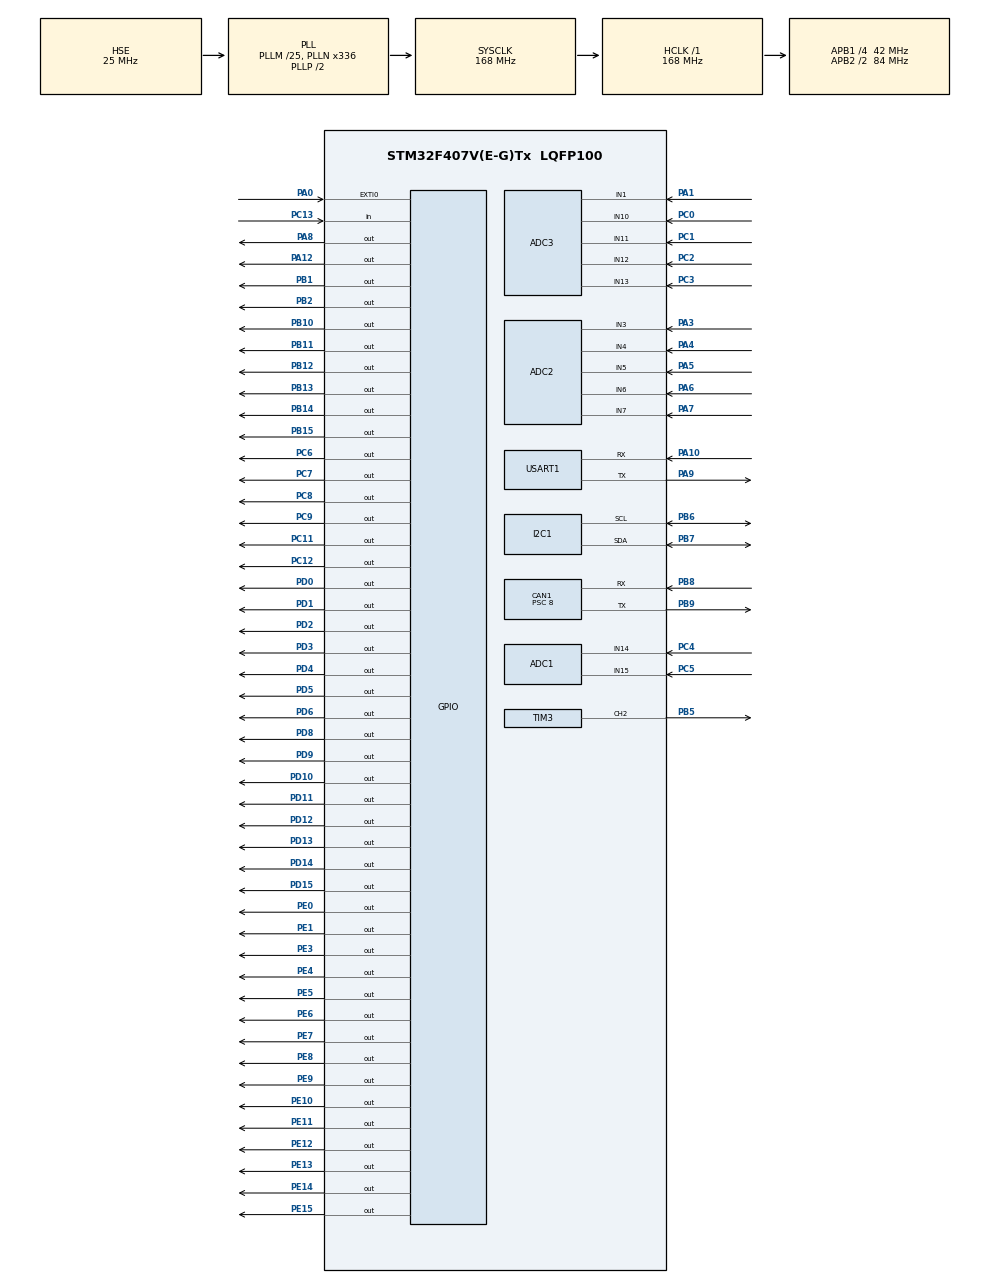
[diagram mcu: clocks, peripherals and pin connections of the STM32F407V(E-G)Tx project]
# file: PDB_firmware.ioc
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ADC1.Channel-0\#ChannelRegularConversion=ADC_CHANNEL_14
ADC1.Channel-1\#ChannelRegularConversion=ADC_CHANNEL_15
ADC1.ClockPrescaler=ADC_CLOCK_SYNC_PCLK_DIV4
ADC1.ContinuousConvMode=ENABLE
ADC1.DMAContinuousRequests=ENABLE
ADC1.NbrOfConversion=2
ADC1.NbrOfConversionFlag=1
ADC1.Rank-0\#ChannelRegularConversion=1
ADC1.Rank-1\#ChannelRegularConversion=2
ADC1.SamplingTime-0\#ChannelRegularConversion=ADC_SAMPLETIME_3CYCLES
ADC1.SamplingTime-1\#ChannelRegularConversion=ADC_SAMPLETIME_3CYCLES
ADC1.master=1
ADC2.Channel-0\#ChannelRegularConversion=ADC_CHANNEL_3
ADC2.Channel-1\#ChannelRegularConversion=ADC_CHANNEL_4
ADC2.Channel-2\#ChannelRegularConversion=ADC_CHANNEL_5
ADC2.Channel-3\#ChannelRegularConversion=ADC_CHANNEL_6
ADC2.Channel-4\#ChannelRegularConversion=ADC_CHANNEL_7
ADC2.ClockPrescaler=ADC_CLOCK_SYNC_PCLK_DIV4
ADC2.ContinuousConvMode=ENABLE
ADC2.DMAContinuousRequests=ENABLE
ADC2.NbrOfConversion=5
ADC2.NbrOfConversionFlag=1
ADC2.Rank-0\#ChannelRegularConversion=1
ADC2.Rank-1\#ChannelRegularConversion=2
ADC2.Rank-2\#ChannelRegularConversion=3
ADC2.Rank-3\#ChannelRegularConversion=4
ADC2.Rank-4\#ChannelRegularConversion=5
ADC2.SamplingTime-0\#ChannelRegularConversion=ADC_SAMPLETIME_3CYCLES
ADC2.SamplingTime-1\#ChannelRegularConversion=ADC_SAMPLETIME_3CYCLES
ADC2.SamplingTime-2\#ChannelRegularConversion=ADC_SAMPLETIME_3CYCLES
ADC2.SamplingTime-3\#ChannelRegularConversion=ADC_SAMPLETIME_3CYCLES
ADC2.SamplingTime-4\#ChannelRegularConversion=ADC_SAMPLETIME_3CYCLES
ADC3.Channel-0\#ChannelRegularConversion=ADC_CHANNEL_10
ADC3.Channel-1\#ChannelRegularConversion=ADC_CHANNEL_11
ADC3.Channel-2\#ChannelRegularConversion=ADC_CHANNEL_12
ADC3.Channel-3\#ChannelRegularConversion=ADC_CHANNEL_13
ADC3.Channel-4\#ChannelRegularConversion=ADC_CHANNEL_1
ADC3.ClockPrescaler=ADC_CLOCK_SYNC_PCLK_DIV4
ADC3.DMAContinuousRequests=ENABLE
ADC3.NbrOfConversion=5
ADC3.NbrOfConversionFlag=1
ADC3.Rank-0\#ChannelRegularConversion=1
ADC3.Rank-1\#ChannelRegularConversion=2
ADC3.Rank-2\#ChannelRegularConversion=3
ADC3.Rank-3\#ChannelRegularConversion=4
ADC3.Rank-4\#ChannelRegularConversion=5
ADC3.SamplingTime-0\#ChannelRegularConversion=ADC_SAMPLETIME_3CYCLES
ADC3.SamplingTime-1\#ChannelRegularConversion=ADC_SAMPLETIME_3CYCLES
ADC3.SamplingTime-2\#ChannelRegularConversion=ADC_SAMPLETIME_3CYCLES
ADC3.SamplingTime-3\#ChannelRegularConversion=ADC_SAMPLETIME_3CYCLES
ADC3.SamplingTime-4\#ChannelRegularConversion=ADC_SAMPLETIME_3CYCLES
CAN1.BS1=CAN_BS1_14TQ
CAN1.BS2=CAN_BS2_6TQ
CAN1.CalculateBaudRate=250000
CAN1.CalculateTimeBit=4000
CAN1.CalculateTimeQuantum=190.47619047619048
CAN1.Prescaler=8
Dma.ADC1.0.Direction=DMA_PERIPH_TO_MEMORY
Dma.ADC1.0.FIFOMode=DMA_FIFOMODE_DISABLE
Dma.ADC1.0.Instance=DMA2_Stream0
Dma.ADC1.0.MemDataAlignment=DMA_MDATAALIGN_HALFWORD
Dma.ADC1.0.MemInc=DMA_MINC_ENABLE
Dma.ADC1.0.Mode=DMA_NORMAL
Dma.ADC1.0.PeriphDataAlignment=DMA_PDATAALIGN_HALFWORD
Dma.ADC1.0.PeriphInc=DMA_PINC_DISABLE
Dma.ADC1.0.Priority=DMA_PRIORITY_LOW
Dma.ADC2.1.Direction=DMA_PERIPH_TO_MEMORY
Dma.ADC2.1.FIFOMode=DMA_FIFOMODE_DISABLE
Dma.ADC2.1.Instance=DMA2_Stream2
Dma.ADC2.1.MemDataAlignment=DMA_MDATAALIGN_HALFWORD
Dma.ADC2.1.MemInc=DMA_MINC_ENABLE
Dma.ADC2.1.Mode=DMA_NORMAL
Dma.ADC2.1.PeriphDataAlignment=DMA_PDATAALIGN_HALFWORD
Dma.ADC2.1.PeriphInc=DMA_PINC_DISABLE
Dma.ADC2.1.Priority=DMA_PRIORITY_VERY_HIGH
Dma.ADC3.2.Direction=DMA_PERIPH_TO_MEMORY
Dma.ADC3.2.FIFOMode=DMA_FIFOMODE_DISABLE
Dma.ADC3.2.Instance=DMA2_Stream1
Dma.ADC3.2.MemDataAlignment=DMA_MDATAALIGN_HALFWORD
Dma.ADC3.2.MemInc=DMA_MINC_ENABLE
Dma.ADC3.2.Mode=DMA_NORMAL
Dma.ADC3.2.PeriphDataAlignment=DMA_PDATAALIGN_HALFWORD
Dma.ADC3.2.PeriphInc=DMA_PINC_DISABLE
Dma.ADC3.2.Priority=DMA_PRIORITY_LOW
Dma.Request0=ADC1
Dma.Request1=ADC2
Dma.Request2=ADC3
FREERTOS.CountingSemaphores01=OLEDoccupiedSem,32,Dynamic,NULL
FREERTOS.Events01=MonitorAnalyzeEvent,Dynamic,NULL;CanReceiveEvent,Dynamic,NULL
FREERTOS.INCLUDE_xEventGroupSetBitFromISR=1
FREERTOS.Queues01=AVDataQueue,32,uint8_t,0,Dynamic,NULL,NULL;AVErrorQueue,16,uint16_t,0,Dynamic,NULL,NULL;CanReceiveQueue,16,uint8_t,0,Dynamic,NULL,NULL;OLEDtoCANerrorSend,8,uint16_t,0,Dynamic,NULL,NULL
FREERTOS.Tasks01=CanErrorSendTas,48,128,Start_CAN_Error_Send_Task,Default,NULL,Dynamic,NULL,NULL;BATdetectTask,8,128,Start_BAT_Detect_Task,Default,NULL,Dynamic,NULL,NULL;OLEDmonitorTask,40,128,Start_OLED_Monitor_Task,Default,NULL,Dynamic,NULL,NULL;CanDataSendTask,48,128,Start_CAN_Data_Send_Task,Default,NULL,Dynamic,NULL,NULL;CANreceiveTask,48,128,Start_CAN_Receive_Task,Default,NULL,Dynamic,NULL,NULL;HSDctrlTask,48,128,Start_HSD_Ctrl_Task,Default,NULL,Dynamic,NULL,NULL;DRSctrlTask,8,128,Start_DRS_Ctrl_Task,Default,NULL,Dynamic,NULL,NULL;WakeupTask,8,128,Start_Wakeup_Task,Default,NULL,Dynamic,NULL,NULL;StandbyTask,55,128,Start_Standby_Task,Default,NULL,Dynamic,NULL,NULL;HSD1diagnosTask,8,128,Start_HSD1_Diagnose_Task,Default,NULL,Dynamic,NULL,NULL;HSD2diagnosTask,8,128,Start_HSD2_Diagnose_Task,Default,NULL,Dynamic,NULL,NULL;CPUTask,8,256,Start_CPU_Task,Default,NULL,Dynamic,NULL,NULL
I2C1.I2C_Mode=I2C_Fast
Mcu.Family=STM32F4
Mcu.Name=STM32F407V(E-G)Tx
Mcu.Package=LQFP100
NVIC.CAN1_RX0_IRQn=true\:5\:0\:true\:false\:true\:true\:true\:true\:true
NVIC.DMA2_Stream0_IRQn=true\:5\:0\:false\:false\:true\:true\:false\:true\:true
NVIC.DMA2_Stream1_IRQn=true\:5\:0\:false\:false\:true\:true\:false\:true\:true
NVIC.DMA2_Stream2_IRQn=true\:5\:0\:false\:false\:true\:true\:false\:true\:true
NVIC.EXTI0_IRQn=true\:5\:0\:false\:false\:true\:true\:true\:true\:true
NVIC.PriorityGroup=NVIC_PRIORITYGROUP_4
NVIC.TIM6_DAC_IRQn=true\:5\:0\:true\:false\:true\:true\:true\:true\:true
NVIC.TIM8_TRG_COM_TIM14_IRQn=true\:15\:0\:false\:false\:true\:false\:false\:true\:true
NVIC.TimeBase=TIM8_TRG_COM_TIM14_IRQn
NVIC.TimeBaseIP=TIM14
PA0-WKUP.GPIO_ModeDefaultEXTI=GPIO_MODE_IT_FALLING
PA0-WKUP.Signal=GPXTI0
PA1.Signal=ADCx_IN1
PA10.Mode=Asynchronous
PA10.Signal=USART1_RX
PA12.Signal=GPIO_Output
PA13.Mode=Serial_Wire
PA13.Signal=SYS_JTMS-SWDIO
PA14.Mode=Serial_Wire
PA14.Signal=SYS_JTCK-SWCLK
PA3.Signal=ADCx_IN3
PA4.Signal=ADCx_IN4
PA5.Signal=ADCx_IN5
PA6.Signal=ADCx_IN6
PA7.Signal=ADCx_IN7
PA8.Signal=GPIO_Output
PA9.Mode=Asynchronous
PA9.Signal=USART1_TX
PB1.Signal=GPIO_Output
PB10.Signal=GPIO_Output
PB11.Signal=GPIO_Output
PB12.Signal=GPIO_Output
PB13.Signal=GPIO_Output
PB14.Signal=GPIO_Output
PB15.Signal=GPIO_Output
PB2.Signal=GPIO_Output
PB5.GPIO_Speed=GPIO_SPEED_FREQ_HIGH
PB5.Signal=S_TIM3_CH2
PB6.GPIO_Pu=GPIO_PULLUP
PB6.Mode=I2C
PB6.Signal=I2C1_SCL
PB7.GPIO_Pu=GPIO_PULLUP
PB7.Mode=I2C
PB7.Signal=I2C1_SDA
PB8.GPIO_PuPd=GPIO_PULLUP
PB8.Mode=CAN_Activate
PB8.Signal=CAN1_RX
PB9.GPIO_PuPd=GPIO_PULLUP
PB9.Mode=CAN_Activate
PB9.Signal=CAN1_TX
PC0.Signal=ADCx_IN10
PC1.Signal=ADCx_IN11
PC11.Signal=GPIO_Output
PC12.Signal=GPIO_Output
PC13-ANTI_TAMP.Signal=GPIO_Input
PC2.Signal=ADCx_IN12
PC3.Signal=ADCx_IN13
PC4.Signal=ADCx_IN14
PC5.Signal=ADCx_IN15
PC6.Signal=GPIO_Output
PC7.Signal=GPIO_Output
PC8.Signal=GPIO_Output
PC9.Signal=GPIO_Output
PD0.Signal=GPIO_Output
PD1.Signal=GPIO_Output
PD10.Signal=GPIO_Output
PD11.Signal=GPIO_Output
PD12.Signal=GPIO_Output
PD13.Signal=GPIO_Output
PD14.Signal=GPIO_Output
PD15.Signal=GPIO_Output
PD2.Signal=GPIO_Output
PD3.Signal=GPIO_Output
PD4.Signal=GPIO_Output
PD5.Signal=GPIO_Output
PD6.Signal=GPIO_Output
PD8.Signal=GPIO_Output
PD9.Signal=GPIO_Output
PE0.Signal=GPIO_Output
PE1.Signal=GPIO_Output
PE10.Signal=GPIO_Output
PE11.Signal=GPIO_Output
PE12.Signal=GPIO_Output
PE13.Signal=GPIO_Output
PE14.Signal=GPIO_Output
PE15.Signal=GPIO_Output
PE3.Signal=GPIO_Output
PE4.Signal=GPIO_Output
PE5.Signal=GPIO_Output
PE6.Signal=GPIO_Output
PE7.Signal=GPIO_Output
PE8.Signal=GPIO_Output
PE9.Signal=GPIO_Output
PH0-OSC_IN.Mode=HSE-External-Oscillator
PH0-OSC_IN.Signal=RCC_OSC_IN
PH1-OSC_OUT.Mode=HSE-External-Oscillator
PH1-OSC_OUT.Signal=RCC_OSC_OUT
ProjectManager.HeapSize=0x200
ProjectManager.StackSize=0x400
ProjectManager.TargetToolchain=MDK-ARM V5.32
RCC.48MHZClocksFreq_Value=84000000
RCC.AHBFreq_Value=168000000
RCC.APB1CLKDivider=RCC_HCLK_DIV4
RCC.APB1Freq_Value=42000000
RCC.APB1TimFreq_Value=84000000
RCC.APB2CLKDivider=RCC_HCLK_DIV2
RCC.APB2Freq_Value=84000000
RCC.APB2TimFreq_Value=168000000
RCC.CortexFreq_Value=168000000
RCC.HCLKFreq_Value=168000000
RCC.HSE_VALUE=25000000
RCC.HSI_VALUE=16000000
RCC.LSE_VALUE=32768
RCC.PLLM=25
RCC.PLLN=336
RCC.PLLSourceVirtual=RCC_PLLSOURCE_HSE
RCC.SYSCLKFreq_VALUE=168000000
RCC.SYSCLKSource=RCC_SYSCLKSOURCE_PLLCLK
RCC.VCOOutputFreq_Value=336000000
SH.ADCx_IN1.0=ADC3_IN1,IN1
SH.ADCx_IN10.0=ADC3_IN10,IN10
SH.ADCx_IN11.0=ADC3_IN11,IN11
SH.ADCx_IN12.0=ADC3_IN12,IN12
SH.ADCx_IN13.0=ADC3_IN13,IN13
SH.ADCx_IN14.0=ADC1_IN14,IN14
SH.ADCx_IN15.0=ADC1_IN15,IN15
SH.ADCx_IN3.0=ADC2_IN3,IN3
SH.ADCx_IN4.0=ADC2_IN4,IN4
SH.ADCx_IN5.0=ADC2_IN5,IN5
SH.ADCx_IN6.0=ADC2_IN6,IN6
SH.ADCx_IN7.0=ADC2_IN7,IN7
SH.S_TIM3_CH2.0=TIM3_CH2,PWM Generation2 CH2
TIM3.Channel-PWM\ Generation2\ CH2=TIM_CHANNEL_2
TIM3.Period=99
TIM3.Prescaler=1679
TIM4.Period=999
TIM4.Prescaler=1679
TIM6.Period=209
TIM6.Prescaler=19
USART1.VirtualMode=VM_ASYNC
VP_FREERTOS_VS_CMSIS_V2.Mode=CMSIS_V2
VP_SYS_VS_tim14.Mode=TIM14
VP_TIM3_VS_ClockSourceINT.Mode=Internal
VP_TIM4_VS_ClockSourceINT.Mode=Internal
VP_TIM6_VS_ClockSourceINT.Mode=Enable_Timer
board=custom

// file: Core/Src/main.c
/* USER CODE BEGIN Header */
/**
  ******************************************************************************
  * @file           : main.c
  * @brief          : Main program body
  ******************************************************************************
  * @attention
  *
  * Copyright (c) 2024 STMicroelectronics.
  * All rights reserved.
  *
  * This software is licensed under terms that can be found in the LICENSE file
  * in the root directory of this software component.
  * If no LICENSE file comes with this software, it is provided AS-IS.
  *
  ******************************************************************************
  */
/* USER CODE END Header */
#include "main.h"
#include "cmsis_os.h"
#include "adc.h"
#include "can.h"
#include "dma.h"
#include "i2c.h"
#include "tim.h"
#include "usart.h"
#include "gpio.h"

/* USER CODE BEGIN Includes */
//bsp
#include "hsd_drive.h"
#include "mycan.h"
#include "oled.h"
#include "oledfont.h"
#include "myusart.h"
#include "voltage_monitor.h"
//app
#include "can_app.h"
#include "oled_app.h"
/* USER CODE END Includes */

void SystemClock_Config(void);
void MX_FREERTOS_Init(void);

/* USER CODE BEGIN 0 */
//分析32位bit数呈现为二进制时1的个数
int count_one_bits(unsigned int value)
{
  int count = 0;
  while (value)
  {
    value &= (value - 1);//
    count++;
  }
  return count;
}

/* USER CODE END 0 */

int main(void)
{

  /* MCU Configuration--------------------------------------------------------*/

  /* Reset of all peripherals, Initializes the Flash interface and the Systick. */
  HAL_Init();

  /* Configure the system clock */
  SystemClock_Config();

  /* Initialize all configured peripherals */
  MX_GPIO_Init();
  MX_DMA_Init();
  MX_ADC1_Init();
  MX_ADC2_Init();
  MX_ADC3_Init();
  MX_CAN1_Init();
  MX_USART1_UART_Init();
  MX_I2C1_Init();
  MX_TIM3_Init();
  MX_TIM6_Init();
  MX_TIM4_Init();

  /* Init scheduler */
  osKernelInitialize();

  /* Call init function for freertos objects (in freertos.c) */
  MX_FREERTOS_Init();

  /* Start scheduler */
  osKernelStart();

  /* We should never get here as control is now taken by the scheduler */
  /* Infinite loop */
  while (1)
  {

  }
}

void SystemClock_Config(void)
{
  RCC_OscInitTypeDef RCC_OscInitStruct = {0};
  RCC_ClkInitTypeDef RCC_ClkInitStruct = {0};

  /** Configure the main internal regulator output voltage
  */
  __HAL_RCC_PWR_CLK_ENABLE();
  __HAL_PWR_VOLTAGESCALING_CONFIG(PWR_REGULATOR_VOLTAGE_SCALE1);

  /** Initializes the RCC Oscillators according to the specified parameters
  * in the RCC_OscInitTypeDef structure.
  */
  RCC_OscInitStruct.OscillatorType = RCC_OSCILLATORTYPE_HSE;
  RCC_OscInitStruct.HSEState = RCC_HSE_ON;
  RCC_OscInitStruct.PLL.PLLState = RCC_PLL_ON;
  RCC_OscInitStruct.PLL.PLLSource = RCC_PLLSOURCE_HSE;
  RCC_OscInitStruct.PLL.PLLM = 25;
  RCC_OscInitStruct.PLL.PLLN = 336;
  RCC_OscInitStruct.PLL.PLLP = RCC_PLLP_DIV2;
  RCC_OscInitStruct.PLL.PLLQ = 4;
  if (HAL_RCC_OscConfig(&RCC_OscInitStruct) != HAL_OK)
  {
    Error_Handler();
  }

  /** Initializes the CPU, AHB and APB buses clocks
  */
  RCC_ClkInitStruct.ClockType = RCC_CLOCKTYPE_HCLK|RCC_CLOCKTYPE_SYSCLK
                              |RCC_CLOCKTYPE_PCLK1|RCC_CLOCKTYPE_PCLK2;
  RCC_ClkInitStruct.SYSCLKSource = RCC_SYSCLKSOURCE_PLLCLK;
  RCC_ClkInitStruct.AHBCLKDivider = RCC_SYSCLK_DIV1;
  RCC_ClkInitStruct.APB1CLKDivider = RCC_HCLK_DIV4;
  RCC_ClkInitStruct.APB2CLKDivider = RCC_HCLK_DIV2;

  if (HAL_RCC_ClockConfig(&RCC_ClkInitStruct, FLASH_LATENCY_5) != HAL_OK)
  {
    Error_Handler();
  }
}

void HAL_TIM_PeriodElapsedCallback(TIM_HandleTypeDef *htim)
{
  if (htim->Instance == TIM14) {
    HAL_IncTick();
  }
}

void Error_Handler(void)
{
  __disable_irq();
  while (1)
  {
  }
}

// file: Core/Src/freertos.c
/* USER CODE BEGIN Header */
/**
  ******************************************************************************
  * File Name          : freertos.c
  * Description        : Code for freertos applications
  ******************************************************************************
  * @attention
  *
  * Copyright (c) 2024 STMicroelectronics.
  * All rights reserved.
  *
  * This software is licensed under terms that can be found in the LICENSE file
  * in the root directory of this software component.
  * If no LICENSE file comes with this software, it is provided AS-IS.
  *
  ******************************************************************************
  */
/* USER CODE END Header */

#include "FreeRTOS.h"
#include "task.h"
#include "main.h"
#include "cmsis_os.h"

/* USER CODE BEGIN Includes */
//mx
#include "tim.h"
//bsp
#include "hsd_drive.h"
#include "mycan.h"
#include "oled.h"
#include "oledfont.h"
#include "myusart.h"
#include "voltage_monitor.h"
#include "standby.h"
//app
#include "monitor_app.h"
#include "can_app.h"
#include "oled_app.h"
//freertos
#include "queue.h"
#include "stream_buffer.h"
#include "event_groups.h"
#include "semphr.h"
/* USER CODE END Includes */

/* Definitions for CanErrorSendTas */
osThreadId_t CanErrorSendTasHandle;
const osThreadAttr_t CanErrorSendTas_attributes = {
  .name = "CanErrorSendTas",
  .stack_size = 128 * 4,
  .priority = (osPriority_t) osPriorityRealtime,
};
/* Definitions for BATdetectTask */
osThreadId_t BATdetectTaskHandle;
const osThreadAttr_t BATdetectTask_attributes = {
  .name = "BATdetectTask",
  .stack_size = 128 * 4,
  .priority = (osPriority_t) osPriorityLow,
};
/* Definitions for OLEDmonitorTask */
osThreadId_t OLEDmonitorTaskHandle;
const osThreadAttr_t OLEDmonitorTask_attributes = {
  .name = "OLEDmonitorTask",
  .stack_size = 128 * 4,
  .priority = (osPriority_t) osPriorityHigh,
};
/* Definitions for CanDataSendTask */
osThreadId_t CanDataSendTaskHandle;
const osThreadAttr_t CanDataSendTask_attributes = {
  .name = "CanDataSendTask",
  .stack_size = 128 * 4,
  .priority = (osPriority_t) osPriorityRealtime,
};
/* Definitions for CANreceiveTask */
osThreadId_t CANreceiveTaskHandle;
const osThreadAttr_t CANreceiveTask_attributes = {
  .name = "CANreceiveTask",
  .stack_size = 128 * 4,
  .priority = (osPriority_t) osPriorityRealtime,
};
/* Definitions for HSDctrlTask */
osThreadId_t HSDctrlTaskHandle;
const osThreadAttr_t HSDctrlTask_attributes = {
  .name = "HSDctrlTask",
  .stack_size = 128 * 4,
  .priority = (osPriority_t) osPriorityRealtime,
};
/* Definitions for DRSctrlTask */
osThreadId_t DRSctrlTaskHandle;
const osThreadAttr_t DRSctrlTask_attributes = {
  .name = "DRSctrlTask",
  .stack_size = 128 * 4,
  .priority = (osPriority_t) osPriorityLow,
};
/* Definitions for WakeupTask */
osThreadId_t WakeupTaskHandle;
const osThreadAttr_t WakeupTask_attributes = {
  .name = "WakeupTask",
  .stack_size = 128 * 4,
  .priority = (osPriority_t) osPriorityLow,
};
/* Definitions for StandbyTask */
osThreadId_t StandbyTaskHandle;
const osThreadAttr_t StandbyTask_attributes = {
  .name = "StandbyTask",
  .stack_size = 128 * 4,
  .priority = (osPriority_t) osPriorityRealtime7,
};
/* Definitions for HSD1diagnosTask */
osThreadId_t HSD1diagnosTaskHandle;
const osThreadAttr_t HSD1diagnosTask_attributes = {
  .name = "HSD1diagnosTask",
  .stack_size = 128 * 4,
  .priority = (osPriority_t) osPriorityLow,
};
/* Definitions for HSD2diagnosTask */
osThreadId_t HSD2diagnosTaskHandle;
const osThreadAttr_t HSD2diagnosTask_attributes = {
  .name = "HSD2diagnosTask",
  .stack_size = 128 * 4,
  .priority = (osPriority_t) osPriorityLow,
};
/* Definitions for CPUTask */
osThreadId_t CPUTaskHandle;
const osThreadAttr_t CPUTask_attributes = {
  .name = "CPUTask",
  .stack_size = 256 * 4,
  .priority = (osPriority_t) osPriorityLow,
};
/* Definitions for AVDataQueue */
osMessageQueueId_t AVDataQueueHandle;
const osMessageQueueAttr_t AVDataQueue_attributes = {
  .name = "AVDataQueue"
};
/* Definitions for AVErrorQueue */
osMessageQueueId_t AVErrorQueueHandle;
const osMessageQueueAttr_t AVErrorQueue_attributes = {
  .name = "AVErrorQueue"
};
/* Definitions for CanReceiveQueue */
osMessageQueueId_t CanReceiveQueueHandle;
const osMessageQueueAttr_t CanReceiveQueue_attributes = {
  .name = "CanReceiveQueue"
};
/* Definitions for OLEDtoCANerrorSend */
osMessageQueueId_t OLEDtoCANerrorSendHandle;
const osMessageQueueAttr_t OLEDtoCANerrorSend_attributes = {
  .name = "OLEDtoCANerrorSend"
};
/* Definitions for OLEDoccupiedSem */
osSemaphoreId_t OLEDoccupiedSemHandle;
const osSemaphoreAttr_t OLEDoccupiedSem_attributes = {
  .name = "OLEDoccupiedSem"
};
/* Definitions for MonitorAnalyzeEvent */
osEventFlagsId_t MonitorAnalyzeEventHandle;
const osEventFlagsAttr_t MonitorAnalyzeEvent_attributes = {
  .name = "MonitorAnalyzeEvent"
};
/* Definitions for CanReceiveEvent */
osEventFlagsId_t CanReceiveEventHandle;
const osEventFlagsAttr_t CanReceiveEvent_attributes = {
  .name = "CanReceiveEvent"
};

void Start_CAN_Error_Send_Task(void *argument);
void Start_BAT_Detect_Task(void *argument);
void Start_OLED_Monitor_Task(void *argument);
void Start_CAN_Data_Send_Task(void *argument);
void Start_CAN_Receive_Task(void *argument);
void Start_HSD_Ctrl_Task(void *argument);
void Start_DRS_Ctrl_Task(void *argument);
void Start_Wakeup_Task(void *argument);
void Start_Standby_Task(void *argument);
void Start_HSD1_Diagnose_Task(void *argument);
void Start_HSD2_Diagnose_Task(void *argument);
void Start_CPU_Task(void *argument);

void MX_FREERTOS_Init(void); /* (MISRA C 2004 rule 8.1) */

void MX_FREERTOS_Init(void) {
  /* USER CODE BEGIN Init */

	uint8_t i=0;	//起始0个错误
	unsigned char Oled_First_Text[8]="Error  0";
	extern uint8_t trigger;

	myprintf("into freertos init\r\n");

  //OLED init
	OLED_Init();
//	OLED_DrawBMP (0, 0,128, 8,(unsigned char*)WUTE);

	//include can init、filter_config与start can_tx and en can_rx fifo
	CAN_Init();

//	HAL_Delay(100);
//	osDelay(1000);		//用这个就跳到任务去了

  //HSD open
	HSD_Output_Enable_HSDs(1);
	HAL_GPIO_WritePin(GPIOD, GPIO_PIN_12, 0);	//BUZZER_PWR_EN不响

	//不要用这个函数单个通道控制，这个驱动有问题（建议直接GPIO写PIN，最高效）
//	HSD_Output_Enable_HSDPinx(0xA1,0);

	//oled into monitor state
	OLED_FullyClear();
	Oled_First_Text[7]=i+48;		//需要赋值字符‘'，选择ascii码操作
	OLED_ShowStr(0, 0, (unsigned char*)Oled_First_Text ,1 );

  /* USER CODE END Init */

  /* Create the semaphores(s) */
  /* creation of OLEDoccupiedSem */
  OLEDoccupiedSemHandle = osSemaphoreNew(32, 32, &OLEDoccupiedSem_attributes);

  /* Create the queue(s) */
  /* creation of AVDataQueue */
  AVDataQueueHandle = osMessageQueueNew (32, sizeof(uint8_t), &AVDataQueue_attributes);

  /* creation of AVErrorQueue */
  AVErrorQueueHandle = osMessageQueueNew (16, sizeof(uint16_t), &AVErrorQueue_attributes);

  /* creation of CanReceiveQueue */
  CanReceiveQueueHandle = osMessageQueueNew (16, sizeof(uint8_t), &CanReceiveQueue_attributes);

  /* creation of OLEDtoCANerrorSend */
  OLEDtoCANerrorSendHandle = osMessageQueueNew (8, sizeof(uint16_t), &OLEDtoCANerrorSend_attributes);

  /* Create the thread(s) */
  /* creation of CanErrorSendTas */
  CanErrorSendTasHandle = osThreadNew(Start_CAN_Error_Send_Task, NULL, &CanErrorSendTas_attributes);

  /* creation of BATdetectTask */
  BATdetectTaskHandle = osThreadNew(Start_BAT_Detect_Task, NULL, &BATdetectTask_attributes);

  /* creation of OLEDmonitorTask */
  OLEDmonitorTaskHandle = osThreadNew(Start_OLED_Monitor_Task, NULL, &OLEDmonitorTask_attributes);

  /* creation of CanDataSendTask */
  CanDataSendTaskHandle = osThreadNew(Start_CAN_Data_Send_Task, NULL, &CanDataSendTask_attributes);

  /* creation of CANreceiveTask */
  CANreceiveTaskHandle = osThreadNew(Start_CAN_Receive_Task, NULL, &CANreceiveTask_attributes);

  /* creation of HSDctrlTask */
  HSDctrlTaskHandle = osThreadNew(Start_HSD_Ctrl_Task, NULL, &HSDctrlTask_attributes);

  /* creation of DRSctrlTask */
  DRSctrlTaskHandle = osThreadNew(Start_DRS_Ctrl_Task, NULL, &DRSctrlTask_attributes);

  /* creation of WakeupTask */
  WakeupTaskHandle = osThreadNew(Start_Wakeup_Task, NULL, &WakeupTask_attributes);

  /* creation of StandbyTask */
  StandbyTaskHandle = osThreadNew(Start_Standby_Task, NULL, &StandbyTask_attributes);

  /* creation of HSD1diagnosTask */
  HSD1diagnosTaskHandle = osThreadNew(Start_HSD1_Diagnose_Task, NULL, &HSD1diagnosTask_attributes);

  /* creation of HSD2diagnosTask */
  HSD2diagnosTaskHandle = osThreadNew(Start_HSD2_Diagnose_Task, NULL, &HSD2diagnosTask_attributes);

  /* creation of CPUTask */
  CPUTaskHandle = osThreadNew(Start_CPU_Task, NULL, &CPUTask_attributes);

  /* Create the event(s) */
  /* creation of MonitorAnalyzeEvent */
  MonitorAnalyzeEventHandle = osEventFlagsNew(&MonitorAnalyzeEvent_attributes);

  /* creation of CanReceiveEvent */
  CanReceiveEventHandle = osEventFlagsNew(&CanReceiveEvent_attributes);

}

void Start_CAN_Error_Send_Task(void *argument)
{
  /* USER CODE BEGIN Start_CAN_Error_Send_Task */
  /* Infinite loop */
  CAN_Error_Send_App();
  /* USER CODE END Start_CAN_Error_Send_Task */
}

void Start_BAT_Detect_Task(void *argument)
{
  /* USER CODE BEGIN Start_BAT_Detect_Task */
	BAT_Monitor_App();		//对电压数据监测与处理，唤起其他操作
  /* USER CODE END Start_BAT_Detect_Task */
}

void Start_OLED_Monitor_Task(void *argument)
{
  /* USER CODE BEGIN Start_OLED_Monitor_Task */
	Oled_App();
  /* USER CODE END Start_OLED_Monitor_Task */
}

void Start_CAN_Data_Send_Task(void *argument)
{
  /* USER CODE BEGIN Start_CAN_Data_Send_Task */
  CAN_Data_Send_App();
  /* USER CODE END Start_CAN_Data_Send_Task */
}

void Start_CAN_Receive_Task(void *argument)
{
  /* USER CODE BEGIN Start_CAN_Receive_Task */
	CAN_Recv_App();
  /* USER CODE END Start_CAN_Receive_Task */
}

void Start_HSD_Ctrl_Task(void *argument)
{
  /* USER CODE BEGIN Start_HSD_Ctrl_Task */
	uint8_t command;
	EventBits_t uxBits;			 // 读取事件组的返回值（已配置事件组宽度为24bit）

	//延时3秒后关闭
	osDelay(3000);
	//下面几个通道默认关闭
	HAL_GPIO_WritePin(GPIOE, GPIO_PIN_7, 0);		//TAILLIGHT_PWR_EN 改为L2_24V_Backup
	HAL_GPIO_WritePin(GPIOD, GPIO_PIN_12, 0);	//BUZZER_PWR_EN
	HAL_GPIO_WritePin(GPIOD, GPIO_PIN_1, 0);		//PUMP_PWR_EN
//	HAL_GPIO_WritePin(GPIOD, GPIO_PIN_4, 0);		//FAN1_PWR_EN
//	HAL_GPIO_WritePin(GPIOE, GPIO_PIN_3, 0);		//FAN3_PWR_EN
//	HAL_GPIO_WritePin(GPIOE, GPIO_PIN_1, 0);		//FAN2_PWR_EN

  /* Infinite loop */
  for(;;)
  {
		uxBits = xEventGroupWaitBits(
			CanReceiveEventHandle,		   /* 大电流HSD相关事件（ADC相对通道转换完成（4bit）、发生错误（1bit）、一组处理完成已发出数据（1bit））句柄 */
			BIT_8|BIT_9|BIT_10|BIT_11|BIT_12|BIT_13 , /* 指代VCU、仪表发来can控制指令的事件(设置了4位) */
			pdTRUE,						   /* 事件标志位复位后退出 */
			pdFALSE,					   /* 或关系（不等都置位了才代表事件发生） */
			portMAX_DELAY);				   /* 等无限久 */

	//先不要用这个函数单个通道控制，这个驱动有问题（另外建议直接GPIO写PIN，最高效）
//	HSD_Output_Enable_HSDPinx(0x91, 0);
  if( ( uxBits & BIT_8 ) != 0 )	//尾灯开
  {
      /* xEventGroupWaitBits() returned because just BIT_0 was set. */
		HAL_GPIO_WritePin(GPIOE, GPIO_PIN_7, 1);		//TAILLIGHT_PWR_EN
  }
  if( ( uxBits & BIT_9 ) != 0 )	//尾灯关
  {
      /* xEventGroupWaitBits() returned because just BIT_4 was set. */
		HAL_GPIO_WritePin(GPIOE, GPIO_PIN_7, 0);		//TAILLIGHT_PWR_EN
  }
	if( ( uxBits & BIT_10 ) != 0 )	//水泵开
  {
      /* xEventGroupWaitBits() returned because just BIT_4 was set. */
		HAL_GPIO_WritePin(GPIOD, GPIO_PIN_1, 1);		//PUMP_PWR_EN
  }
	if( ( uxBits & BIT_11 ) != 0 )	//水泵关
  {
      /* xEventGroupWaitBits() returned because just BIT_4 was set. */
		HAL_GPIO_WritePin(GPIOD, GPIO_PIN_1, 0);		//PUMP_PWR_EN
  }
	if( ( uxBits & BIT_12 ) != 0 )	//蜂鸣器开
  {
      /* xEventGroupWaitBits() returned because just BIT_4 was set. */
		HAL_GPIO_WritePin(GPIOD, GPIO_PIN_12, 1);	//BUZZER_PWR_EN
  }
	if( ( uxBits & BIT_13 ) != 0 )	//蜂鸣器关
  {
      /* xEventGroupWaitBits() returned because just BIT_4 was set. */
		HAL_GPIO_WritePin(GPIOD, GPIO_PIN_12, 0);	//BUZZER_PWR_EN
  }
//	else if( ( uxBits & BIT_14 ) != 0 )	//DRS开
//  {
//      /* xEventGroupWaitBits() returned because just BIT_4 was set. */
//		HAL_GPIO_WritePin(GPIOE, GPIO_PIN_6, 1);		//DRS_PWR_8V_EN
//  }
//	else if( ( uxBits & BIT_15 ) != 0 )	//DRS关
//  {
//      /* xEventGroupWaitBits() returned because just BIT_4 was set. */
//		HAL_GPIO_WritePin(GPIOE, GPIO_PIN_6, 0);		//DRS_PWR_8V_EN
//  }
//	else if( ( uxBits & BIT_16 ) != 0 )	//FAN2开
//  {
//      /* xEventGroupWaitBits() returned because just BIT_4 was set. */
//		HAL_GPIO_WritePin(GPIOD, GPIO_PIN_12, 1);	//BUZZER_PWR_EN
//  }
//	else if( ( uxBits & BIT_17 ) != 0 )	//FAN2关
//  {
//      /* xEventGroupWaitBits() returned because just BIT_4 was set. */
//		HAL_GPIO_WritePin(GPIOD, GPIO_PIN_12, 0);	//BUZZER_PWR_EN
//  }
	//回调任务，不延时
//    osDelay(1000);
  }
  /* USER CODE END Start_HSD_Ctrl_Task */
}

void Start_DRS_Ctrl_Task(void *argument)
{
  /* USER CODE BEGIN Start_DRS_Ctrl_Task */
	//
	uint16_t compareValue=0 ;

	BaseType_t xHigherPriorityTaskWoken = pdFALSE, xResult;
	BaseType_t xReturn = pdPASS; /* 定义一个创建信息返回值，默认为pdPASS */
	EventBits_t uxBits;			 // 读取事件组的返回值（已配置事件组宽度为24bit）

  /* Infinite loop */
  for(;;)
  {
		//VCU、仪表发来控制信号（现在还只是设置DRS开关）
		uxBits = xEventGroupWaitBits(
			CanReceiveEventHandle, /* 大电流HSD相关事件（ADC相对通道转换完成（4bit）、发生错误（1bit）、一组处理完成已发出数据（1bit））句柄 */
			BIT_14|BIT_15,	   /* 例子，未定 */
			pdTRUE,				   /* 事件标志位复位后退出 */
			pdFALSE,			   /* 或关系（不等都置位了才代表事件发生） */
			portMAX_DELAY);		   /* 等无限久（既然能过，必然是收到了事件，所以下面不再if判断是否事件真置位） */

		if (( uxBits & BIT_14 ) != 0) // DRS开启
				{
					__HAL_TIM_SET_COMPARE(&htim3, TIM_CHANNEL_2, 100); // 配置比较寄存器(相对于1000的自动重装载值)
					HAL_TIM_PWM_Start(&htim3, TIM_CHANNEL_2);		   // 背光开启，显形
				}
		if (( uxBits & BIT_15 ) != 0) // DRS关闭
				{
					// 现在配置的PWM周期为0.02s，50Hz
					__HAL_TIM_SET_COMPARE(&htim3, TIM_CHANNEL_2, 0); // 配置比较寄存器(相对于1000的自动重装载值)
					HAL_TIM_PWM_Start(&htim3, TIM_CHANNEL_2);		 // 背光开启，显形
				}

		myprintf("DRS ctrl finish");

		//回调任务，不延时
//    osDelay(1000);
  }
  /* USER CODE END Start_DRS_Ctrl_Task */
}

void Start_Wakeup_Task(void *argument)
{
  /* USER CODE BEGIN Start_Wakeup_Task */
	Wakeup_App();
  /* USER CODE END Start_Wakeup_Task */
}

void Start_Standby_Task(void *argument)
{
  /* USER CODE BEGIN Start_Standby_Task */
  Standby_App();
  /* USER CODE END Start_Standby_Task */
}

void Start_HSD1_Diagnose_Task(void *argument)
{
  /* USER CODE BEGIN Start_HSD1_Diagnose_Task */
	//其优先级必须最低，等都处理完再执行，否则错误码未发出就覆盖了（HSD1\HSD2\HSD3共用同一个错误码发送队列，而CAN发送任务仅仅用一个uint16_t 变量接收）
	HSD1_Monitor_App();		//对HSD1采集的电流数据监测与处理，唤起其他操作
  /* USER CODE END Start_HSD1_Diagnose_Task */
}

void Start_HSD2_Diagnose_Task(void *argument)
{
  /* USER CODE BEGIN Start_HSD2_Diagnose_Task */
	HSD2_Monitor_App();		//对HSD2采集的电流数据监测与处理，唤起其他操作
  /* USER CODE END Start_HSD2_Diagnose_Task */
}

void Start_CPU_Task(void *argument)
{
  /* USER CODE BEGIN Start_CPU_Task */

//	uint8_t CPU_RunInfo[400];		//保存任务运行时间信息
//
  /* Infinite loop */
  for(;;)
  {
//		memset(CPU_RunInfo,0,400);				//信息缓冲区清零
//
//    vTaskList((char *)&CPU_RunInfo);  //获取任务运行时间信息
//
//    myprintf("---------------------------------------------\r\n");
//    myprintf("任务名      任务状态 优先级   剩余栈 任务序号\r\n");
//    myprintf("%s", CPU_RunInfo);
//    myprintf("---------------------------------------------\r\n");
//
//    memset(CPU_RunInfo,0,400);				//信息缓冲区清零
//
//    vTaskGetRunTimeStats((char *)&CPU_RunInfo);
//
//    myprintf("任务名       运行计数         使用率\r\n");
//    myprintf("%s", CPU_RunInfo);
//    myprintf("---------------------------------------------\r\n\n");
//    vTaskDelay(1000);   //延时500个tick
    osDelay(1000);
  }
  /* USER CODE END Start_CPU_Task */
}
